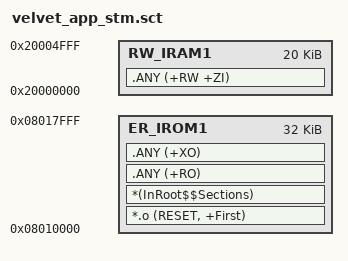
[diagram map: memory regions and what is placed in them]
; ******************************************************************
; *** Scatter-Loading Description File generated by Embedded IDE ***
; ******************************************************************

LR_IROM1 0x08010000 0x00008000 {
	ER_IROM1 0x08010000 0x00008000 {
		*.o (RESET, +First) 
		*(InRoot$$Sections) 
		.ANY (+RO) 
		.ANY (+XO) 
	}
	RW_IRAM1 0x20000000 0x00005000 {
		.ANY (+RW +ZI) 
	}
}

